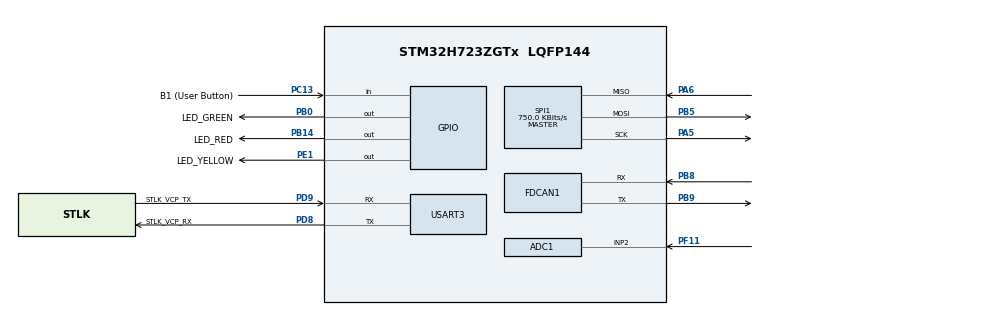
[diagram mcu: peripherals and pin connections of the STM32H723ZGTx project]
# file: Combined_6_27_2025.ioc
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ADC1.Channel-0\#ChannelRegularConversion=ADC_CHANNEL_2
ADC1.ContinuousConvMode=ENABLE
ADC1.ConversionDataManagement=ADC_CONVERSIONDATA_DMA_CIRCULAR
ADC1.EOCSelection=ADC_EOC_SEQ_CONV
ADC1.ExternalTrigConv=ADC_EXTERNALTRIG_T3_TRGO
ADC1.NbrOfConversionFlag=1
ADC1.OffsetNumber-0\#ChannelRegularConversion=ADC_OFFSET_NONE
ADC1.OffsetSignedSaturation-0\#ChannelRegularConversion=DISABLE
ADC1.Rank-0\#ChannelRegularConversion=1
ADC1.Resolution=ADC_RESOLUTION_14B_OPT
ADC1.SamplingTime-0\#ChannelRegularConversion=ADC_SAMPLETIME_64CYCLES_5
ADC1.master=1
CORTEX_M7.default_mode_Activation=1
Dma.ADC1.0.Direction=DMA_PERIPH_TO_MEMORY
Dma.ADC1.0.EventEnable=DISABLE
Dma.ADC1.0.FIFOMode=DMA_FIFOMODE_DISABLE
Dma.ADC1.0.Instance=DMA1_Stream0
Dma.ADC1.0.MemDataAlignment=DMA_MDATAALIGN_HALFWORD
Dma.ADC1.0.MemInc=DMA_MINC_ENABLE
Dma.ADC1.0.Mode=DMA_CIRCULAR
Dma.ADC1.0.PeriphDataAlignment=DMA_PDATAALIGN_HALFWORD
Dma.ADC1.0.PeriphInc=DMA_PINC_DISABLE
Dma.ADC1.0.Polarity=HAL_DMAMUX_REQ_GEN_RISING
Dma.ADC1.0.Priority=DMA_PRIORITY_VERY_HIGH
Dma.ADC1.0.RequestNumber=1
Dma.ADC1.0.SignalID=NONE
Dma.ADC1.0.SyncEnable=DISABLE
Dma.ADC1.0.SyncPolarity=HAL_DMAMUX_SYNC_NO_EVENT
Dma.ADC1.0.SyncRequestNumber=1
Dma.ADC1.0.SyncSignalID=NONE
Dma.Request0=ADC1
FDCAN1.AutoRetransmission=ENABLE
FDCAN1.CalculateBaudRateNominal=500000
FDCAN1.CalculateTimeBitNominal=2000
FDCAN1.CalculateTimeQuantumNominal=20.833333333333332
FDCAN1.DataPrescaler=2
FDCAN1.DataSyncJumpWidth=11
FDCAN1.DataTimeSeg1=12
FDCAN1.DataTimeSeg2=11
FDCAN1.NominalPrescaler=1
FDCAN1.NominalSyncJumpWidth=12
FDCAN1.NominalTimeSeg1=83
FDCAN1.NominalTimeSeg2=12
FDCAN1.RxBufferSize=FDCAN_DATA_BYTES_12
FDCAN1.RxBuffersNbr=1
FDCAN1.RxFifo0ElmtSize=FDCAN_DATA_BYTES_12
FDCAN1.RxFifo1ElmtSize=FDCAN_DATA_BYTES_12
FDCAN1.StdFiltersNbr=1
FDCAN1.TransmitPause=ENABLE
FDCAN1.TxBuffersNbr=1
FDCAN1.TxElmtSize=FDCAN_DATA_BYTES_12
Mcu.Family=STM32H7
Mcu.Name=STM32H723ZGTx
Mcu.Package=LQFP144
NVIC.DMA1_Stream0_IRQn=true\:0\:0\:false\:false\:true\:false\:true\:true
NVIC.PriorityGroup=NVIC_PRIORITYGROUP_4
PA13(JTMS/SWDIO).GPIO_Label=SWDIO
PA13(JTMS/SWDIO).Signal=DEBUG_JTMS-SWDIO
PA14(JTCK/SWCLK).GPIO_Label=SWCLK
PA14(JTCK/SWCLK).Signal=DEBUG_JTCK-SWCLK
PA5.Mode=Full_Duplex_Master
PA5.Signal=SPI1_SCK
PA6.Mode=Full_Duplex_Master
PA6.Signal=SPI1_MISO
PB0.GPIO_Label=LED_GREEN
PB0.Signal=GPIO_Output
PB14.GPIO_Label=LED_RED
PB14.Signal=GPIO_Output
PB5.Mode=Full_Duplex_Master
PB5.Signal=SPI1_MOSI
PB8.Mode=FDCAN_Activate
PB8.Signal=FDCAN1_RX
PB9.Mode=FDCAN_Activate
PB9.Signal=FDCAN1_TX
PC13.GPIO_Label=B1 (User Button)
PC13.Signal=GPIO_Input
PC14-OSC32_IN.Signal=RCC_OSC32_IN
PC15-OSC32_OUT.Signal=RCC_OSC32_OUT
PD8.GPIO_Label=STLK_VCP_RX
PD8.Mode=Asynchronous
PD8.Signal=USART3_TX
PD9.GPIO_Label=STLK_VCP_TX
PD9.Mode=Asynchronous
PD9.Signal=USART3_RX
PE1.GPIO_Label=LED_YELLOW
PE1.Signal=GPIO_Output
PF11.Mode=IN2-Single-Ended
PF11.Signal=ADC1_INP2
ProjectManager.HeapSize=0x200
ProjectManager.StackSize=0x400
ProjectManager.TargetToolchain=STM32CubeIDE
RCC.ADCFreq_Value=48000000
RCC.APB1Freq_Value=96000000
RCC.APB2Freq_Value=96000000
RCC.APB3Freq_Value=96000000
RCC.APB4Freq_Value=96000000
RCC.CortexFreq_Value=192000000
RCC.D1PPRE=RCC_APB3_DIV2
RCC.D2PPRE1=RCC_APB1_DIV2
RCC.D2PPRE2=RCC_APB2_DIV2
RCC.D3PPRE=RCC_APB4_DIV2
RCC.DIVM1=4
RCC.DIVM2=4
RCC.DIVN1=12
RCC.DIVN2=12
RCC.DIVP1=1
RCC.DIVP2=4
RCC.DIVQ1=4
RCC.HCLKFreq_Value=192000000
RCC.HSE_VALUE=8000000
RCC.PLL2FRACN=0
RCC.PLLFRACN=0
RCC.SYSCLKFreq_VALUE=192000000
RCC.SYSCLKSource=RCC_SYSCLKSOURCE_PLLCLK
RCC.USBCLockSelection=RCC_USBCLKSOURCE_HSI48
RCC.USBFreq_Value=48000000
SPI1.BaudRatePrescaler=SPI_BAUDRATEPRESCALER_64
SPI1.CalculateBaudRate=750.0 KBits/s
SPI1.DataSize=SPI_DATASIZE_12BIT
SPI1.Direction=SPI_DIRECTION_2LINES
SPI1.Mode=SPI_MODE_MASTER
SPI1.NSSPMode=SPI_NSS_PULSE_DISABLE
SPI1.VirtualType=VM_MASTER
TIM3.Period=99
TIM3.Prescaler=1919
TIM3.TIM_MasterOutputTrigger=TIM_TRGO_UPDATE
USART3.VirtualMode-Asynchronous=VM_ASYNC
VP_MEMORYMAP_VS_MEMORYMAP.Mode=CurAppReg
VP_TIM3_VS_ClockSourceINT.Mode=Internal
board=NUCLEO-H723ZG

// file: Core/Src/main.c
#include "main.h"

ADC_HandleTypeDef hadc1;
DMA_HandleTypeDef hdma_adc1;
FDCAN_HandleTypeDef hfdcan1;
SPI_HandleTypeDef hspi1;
TIM_HandleTypeDef htim3;
UART_HandleTypeDef huart3;

void SystemClock_Config(void);
 void MPU_Config(void);
 void MX_GPIO_Init(void);
 void MX_DMA_Init(void);
 void MX_ADC1_Init(void);
 void MX_TIM3_Init(void);
 void MX_FDCAN1_Init(void);
 void MX_SPI1_Init(void);
 void MX_USART3_UART_Init(void);

int testmain(void)
{

  /* MPU Configuration--------------------------------------------------------*/
  MPU_Config();

  /* MCU Configuration--------------------------------------------------------*/

  /* Reset of all peripherals, Initializes the Flash interface and the Systick. */
  HAL_Init();

  /* Configure the system clock */
  SystemClock_Config();

  /* Initialize all configured peripherals */
  MX_GPIO_Init();
  MX_DMA_Init();
  MX_ADC1_Init();
  MX_TIM3_Init();
  MX_FDCAN1_Init();
  MX_SPI1_Init();
  MX_USART3_UART_Init();
  /* USER CODE BEGIN 2 */
uint8_t buffer_uart[] = "Hello World";
  /* USER CODE END 2 */

  /* Infinite loop */
  while (1)
  {

  }
}

void SystemClock_Config(void)
{
  RCC_OscInitTypeDef RCC_OscInitStruct = {0};
  RCC_ClkInitTypeDef RCC_ClkInitStruct = {0};

  /** Supply configuration update enable
  */
  HAL_PWREx_ConfigSupply(PWR_LDO_SUPPLY);

  /** Configure the main internal regulator output voltage
  */
  __HAL_PWR_VOLTAGESCALING_CONFIG(PWR_REGULATOR_VOLTAGE_SCALE1);

  while(!__HAL_PWR_GET_FLAG(PWR_FLAG_VOSRDY)) {}

  /** Initializes the RCC Oscillators according to the specified parameters
  * in the RCC_OscInitTypeDef structure.
  */
  RCC_OscInitStruct.OscillatorType = RCC_OSCILLATORTYPE_HSI;
  RCC_OscInitStruct.HSIState = RCC_HSI_DIV1;
  RCC_OscInitStruct.HSICalibrationValue = 64;
  RCC_OscInitStruct.PLL.PLLState = RCC_PLL_ON;
  RCC_OscInitStruct.PLL.PLLSource = RCC_PLLSOURCE_HSI;
  RCC_OscInitStruct.PLL.PLLM = 4;
  RCC_OscInitStruct.PLL.PLLN = 12;
  RCC_OscInitStruct.PLL.PLLP = 1;
  RCC_OscInitStruct.PLL.PLLQ = 4;
  RCC_OscInitStruct.PLL.PLLR = 2;
  RCC_OscInitStruct.PLL.PLLRGE = RCC_PLL1VCIRANGE_3;
  RCC_OscInitStruct.PLL.PLLVCOSEL = RCC_PLL1VCOWIDE;
  RCC_OscInitStruct.PLL.PLLFRACN = 0;
  if (HAL_RCC_OscConfig(&RCC_OscInitStruct) != HAL_OK)
  {
    Error_Handler();
  }

  /** Initializes the CPU, AHB and APB buses clocks
  */
  RCC_ClkInitStruct.ClockType = RCC_CLOCKTYPE_HCLK|RCC_CLOCKTYPE_SYSCLK
                              |RCC_CLOCKTYPE_PCLK1|RCC_CLOCKTYPE_PCLK2
                              |RCC_CLOCKTYPE_D3PCLK1|RCC_CLOCKTYPE_D1PCLK1;
  RCC_ClkInitStruct.SYSCLKSource = RCC_SYSCLKSOURCE_PLLCLK;
  RCC_ClkInitStruct.SYSCLKDivider = RCC_SYSCLK_DIV1;
  RCC_ClkInitStruct.AHBCLKDivider = RCC_HCLK_DIV1;
  RCC_ClkInitStruct.APB3CLKDivider = RCC_APB3_DIV2;
  RCC_ClkInitStruct.APB1CLKDivider = RCC_APB1_DIV2;
  RCC_ClkInitStruct.APB2CLKDivider = RCC_APB2_DIV2;
  RCC_ClkInitStruct.APB4CLKDivider = RCC_APB4_DIV2;

  if (HAL_RCC_ClockConfig(&RCC_ClkInitStruct, FLASH_LATENCY_2) != HAL_OK)
  {
    Error_Handler();
  }
}

void MX_ADC1_Init(void)
{

  ADC_MultiModeTypeDef multimode = {0};
  ADC_ChannelConfTypeDef sConfig = {0};

  /** Common config
  */
  hadc1.Instance = ADC1;
  hadc1.Init.ClockPrescaler = ADC_CLOCK_ASYNC_DIV1;
  hadc1.Init.Resolution = ADC_RESOLUTION_14B;
  hadc1.Init.ScanConvMode = ADC_SCAN_DISABLE;
  hadc1.Init.EOCSelection = ADC_EOC_SEQ_CONV;
  hadc1.Init.LowPowerAutoWait = DISABLE;
  hadc1.Init.ContinuousConvMode = ENABLE;
  hadc1.Init.NbrOfConversion = 1;
  hadc1.Init.DiscontinuousConvMode = DISABLE;
  hadc1.Init.ExternalTrigConv = ADC_EXTERNALTRIG_T3_TRGO;
  hadc1.Init.ExternalTrigConvEdge = ADC_EXTERNALTRIGCONVEDGE_RISING;
  hadc1.Init.ConversionDataManagement = ADC_CONVERSIONDATA_DMA_CIRCULAR;
  hadc1.Init.Overrun = ADC_OVR_DATA_PRESERVED;
  hadc1.Init.LeftBitShift = ADC_LEFTBITSHIFT_NONE;
  hadc1.Init.OversamplingMode = DISABLE;
  hadc1.Init.Oversampling.Ratio = 1;
  if (HAL_ADC_Init(&hadc1) != HAL_OK)
  {
    Error_Handler();
  }

  /** Configure the ADC multi-mode
  */
  multimode.Mode = ADC_MODE_INDEPENDENT;
  if (HAL_ADCEx_MultiModeConfigChannel(&hadc1, &multimode) != HAL_OK)
  {
    Error_Handler();
  }

  /** Configure Regular Channel
  */
  sConfig.Channel = ADC_CHANNEL_2;
  sConfig.Rank = ADC_REGULAR_RANK_1;
  sConfig.SamplingTime = ADC_SAMPLETIME_64CYCLES_5;
  sConfig.SingleDiff = ADC_SINGLE_ENDED;
  sConfig.OffsetNumber = ADC_OFFSET_NONE;
  sConfig.Offset = 0;
  sConfig.OffsetSignedSaturation = DISABLE;
  if (HAL_ADC_ConfigChannel(&hadc1, &sConfig) != HAL_OK)
  {
    Error_Handler();
  }

}

void MX_FDCAN1_Init(void)
{

  hfdcan1.Instance = FDCAN1;
  hfdcan1.Init.FrameFormat = FDCAN_FRAME_CLASSIC;
  hfdcan1.Init.Mode = FDCAN_MODE_NORMAL;
  hfdcan1.Init.AutoRetransmission = ENABLE;
  hfdcan1.Init.TransmitPause = DISABLE;
  hfdcan1.Init.ProtocolException = DISABLE;
  hfdcan1.Init.NominalPrescaler = 1;
  hfdcan1.Init.NominalSyncJumpWidth = 12;
  hfdcan1.Init.NominalTimeSeg1 = 83;
  hfdcan1.Init.NominalTimeSeg2 = 12;
  hfdcan1.Init.DataPrescaler = 2;
  hfdcan1.Init.DataSyncJumpWidth = 11;
  hfdcan1.Init.DataTimeSeg1 = 12;
  hfdcan1.Init.DataTimeSeg2 = 11;
  hfdcan1.Init.MessageRAMOffset = 0;
  hfdcan1.Init.StdFiltersNbr = 1;
  hfdcan1.Init.ExtFiltersNbr = 0;
  hfdcan1.Init.RxFifo0ElmtsNbr = 0;
  hfdcan1.Init.RxFifo0ElmtSize = FDCAN_DATA_BYTES_12;
  hfdcan1.Init.RxFifo1ElmtsNbr = 0;
  hfdcan1.Init.RxFifo1ElmtSize = FDCAN_DATA_BYTES_12;
  hfdcan1.Init.RxBuffersNbr = 1;
  hfdcan1.Init.RxBufferSize = FDCAN_DATA_BYTES_12;
  hfdcan1.Init.TxEventsNbr = 0;
  hfdcan1.Init.TxBuffersNbr = 1;
  hfdcan1.Init.TxFifoQueueElmtsNbr = 0;
  hfdcan1.Init.TxFifoQueueMode = FDCAN_TX_FIFO_OPERATION;
  hfdcan1.Init.TxElmtSize = FDCAN_DATA_BYTES_12;
  if (HAL_FDCAN_Init(&hfdcan1) != HAL_OK)
  {
    Error_Handler();
  }

}

void MX_SPI1_Init(void)
{

  /* SPI1 parameter configuration*/
  hspi1.Instance = SPI1;
  hspi1.Init.Mode = SPI_MODE_MASTER;
  hspi1.Init.Direction = SPI_DIRECTION_2LINES;
  hspi1.Init.DataSize = SPI_DATASIZE_12BIT;
  hspi1.Init.CLKPolarity = SPI_POLARITY_LOW;
  hspi1.Init.CLKPhase = SPI_PHASE_1EDGE;
  hspi1.Init.NSS = SPI_NSS_SOFT;
  hspi1.Init.BaudRatePrescaler = SPI_BAUDRATEPRESCALER_64;
  hspi1.Init.FirstBit = SPI_FIRSTBIT_MSB;
  hspi1.Init.TIMode = SPI_TIMODE_DISABLE;
  hspi1.Init.CRCCalculation = SPI_CRCCALCULATION_DISABLE;
  hspi1.Init.CRCPolynomial = 0x0;
  hspi1.Init.NSSPMode = SPI_NSS_PULSE_DISABLE;
  hspi1.Init.NSSPolarity = SPI_NSS_POLARITY_LOW;
  hspi1.Init.FifoThreshold = SPI_FIFO_THRESHOLD_01DATA;
  hspi1.Init.TxCRCInitializationPattern = SPI_CRC_INITIALIZATION_ALL_ZERO_PATTERN;
  hspi1.Init.RxCRCInitializationPattern = SPI_CRC_INITIALIZATION_ALL_ZERO_PATTERN;
  hspi1.Init.MasterSSIdleness = SPI_MASTER_SS_IDLENESS_00CYCLE;
  hspi1.Init.MasterInterDataIdleness = SPI_MASTER_INTERDATA_IDLENESS_00CYCLE;
  hspi1.Init.MasterReceiverAutoSusp = SPI_MASTER_RX_AUTOSUSP_DISABLE;
  hspi1.Init.MasterKeepIOState = SPI_MASTER_KEEP_IO_STATE_DISABLE;
  hspi1.Init.IOSwap = SPI_IO_SWAP_DISABLE;
  if (HAL_SPI_Init(&hspi1) != HAL_OK)
  {
    Error_Handler();
  }

}

void MX_TIM3_Init(void)
{

  TIM_ClockConfigTypeDef sClockSourceConfig = {0};
  TIM_MasterConfigTypeDef sMasterConfig = {0};

  htim3.Instance = TIM3;
  htim3.Init.Prescaler = 1919;
  htim3.Init.CounterMode = TIM_COUNTERMODE_UP;
  htim3.Init.Period = 99;
  htim3.Init.ClockDivision = TIM_CLOCKDIVISION_DIV1;
  htim3.Init.AutoReloadPreload = TIM_AUTORELOAD_PRELOAD_DISABLE;
  if (HAL_TIM_Base_Init(&htim3) != HAL_OK)
  {
    Error_Handler();
  }
  sClockSourceConfig.ClockSource = TIM_CLOCKSOURCE_INTERNAL;
  if (HAL_TIM_ConfigClockSource(&htim3, &sClockSourceConfig) != HAL_OK)
  {
    Error_Handler();
  }
  sMasterConfig.MasterOutputTrigger = TIM_TRGO_UPDATE;
  sMasterConfig.MasterSlaveMode = TIM_MASTERSLAVEMODE_DISABLE;
  if (HAL_TIMEx_MasterConfigSynchronization(&htim3, &sMasterConfig) != HAL_OK)
  {
    Error_Handler();
  }

}

void MX_USART3_UART_Init(void)
{

  huart3.Instance = USART3;
  huart3.Init.BaudRate = 115200;
  huart3.Init.WordLength = UART_WORDLENGTH_8B;
  huart3.Init.StopBits = UART_STOPBITS_1;
  huart3.Init.Parity = UART_PARITY_NONE;
  huart3.Init.Mode = UART_MODE_TX_RX;
  huart3.Init.HwFlowCtl = UART_HWCONTROL_NONE;
  huart3.Init.OverSampling = UART_OVERSAMPLING_16;
  huart3.Init.OneBitSampling = UART_ONE_BIT_SAMPLE_DISABLE;
  huart3.Init.ClockPrescaler = UART_PRESCALER_DIV1;
  huart3.AdvancedInit.AdvFeatureInit = UART_ADVFEATURE_NO_INIT;
  if (HAL_UART_Init(&huart3) != HAL_OK)
  {
    Error_Handler();
  }
  if (HAL_UARTEx_SetTxFifoThreshold(&huart3, UART_TXFIFO_THRESHOLD_1_8) != HAL_OK)
  {
    Error_Handler();
  }
  if (HAL_UARTEx_SetRxFifoThreshold(&huart3, UART_RXFIFO_THRESHOLD_1_8) != HAL_OK)
  {
    Error_Handler();
  }
  if (HAL_UARTEx_DisableFifoMode(&huart3) != HAL_OK)
  {
    Error_Handler();
  }

}

void MX_DMA_Init(void)
{

  /* DMA controller clock enable */
  __HAL_RCC_DMA1_CLK_ENABLE();

  /* DMA interrupt init */
  /* DMA1_Stream0_IRQn interrupt configuration */
  HAL_NVIC_SetPriority(DMA1_Stream0_IRQn, 0, 0);
  HAL_NVIC_EnableIRQ(DMA1_Stream0_IRQn);

}

void MX_GPIO_Init(void)
{
  GPIO_InitTypeDef GPIO_InitStruct = {0};

  /* GPIO Ports Clock Enable */
  __HAL_RCC_GPIOC_CLK_ENABLE();
  __HAL_RCC_GPIOA_CLK_ENABLE();
  __HAL_RCC_GPIOB_CLK_ENABLE();
  __HAL_RCC_GPIOF_CLK_ENABLE();
  __HAL_RCC_GPIOD_CLK_ENABLE();
  __HAL_RCC_GPIOE_CLK_ENABLE();

  /*Configure GPIO pin Output Level */
  HAL_GPIO_WritePin(GPIOB, LED_GREEN_Pin|LED_RED_Pin, GPIO_PIN_RESET);

  /*Configure GPIO pin Output Level */
  HAL_GPIO_WritePin(LED_YELLOW_GPIO_Port, LED_YELLOW_Pin, GPIO_PIN_RESET);

  /*Configure GPIO pin : B1_Pin */
  GPIO_InitStruct.Pin = B1_Pin;
  GPIO_InitStruct.Mode = GPIO_MODE_INPUT;
  GPIO_InitStruct.Pull = GPIO_NOPULL;
  HAL_GPIO_Init(B1_GPIO_Port, &GPIO_InitStruct);

  /*Configure GPIO pins : LED_GREEN_Pin LED_RED_Pin */
  GPIO_InitStruct.Pin = LED_GREEN_Pin|LED_RED_Pin;
  GPIO_InitStruct.Mode = GPIO_MODE_OUTPUT_PP;
  GPIO_InitStruct.Pull = GPIO_NOPULL;
  GPIO_InitStruct.Speed = GPIO_SPEED_FREQ_LOW;
  HAL_GPIO_Init(GPIOB, &GPIO_InitStruct);

  /*Configure GPIO pin : LED_YELLOW_Pin */
  GPIO_InitStruct.Pin = LED_YELLOW_Pin;
  GPIO_InitStruct.Mode = GPIO_MODE_OUTPUT_PP;
  GPIO_InitStruct.Pull = GPIO_NOPULL;
  GPIO_InitStruct.Speed = GPIO_SPEED_FREQ_LOW;
  HAL_GPIO_Init(LED_YELLOW_GPIO_Port, &GPIO_InitStruct);

}

 /* MPU Configuration */

void MPU_Config(void)
{
  MPU_Region_InitTypeDef MPU_InitStruct = {0};

  /* Disables the MPU */
  HAL_MPU_Disable();

  /** Initializes and configures the Region and the memory to be protected
  */
  MPU_InitStruct.Enable = MPU_REGION_ENABLE;
  MPU_InitStruct.Number = MPU_REGION_NUMBER0;
  MPU_InitStruct.BaseAddress = 0x0;
  MPU_InitStruct.Size = MPU_REGION_SIZE_4GB;
  MPU_InitStruct.SubRegionDisable = 0x87;
  MPU_InitStruct.TypeExtField = MPU_TEX_LEVEL0;
  MPU_InitStruct.AccessPermission = MPU_REGION_NO_ACCESS;
  MPU_InitStruct.DisableExec = MPU_INSTRUCTION_ACCESS_DISABLE;
  MPU_InitStruct.IsShareable = MPU_ACCESS_SHAREABLE;
  MPU_InitStruct.IsCacheable = MPU_ACCESS_NOT_CACHEABLE;
  MPU_InitStruct.IsBufferable = MPU_ACCESS_NOT_BUFFERABLE;

  HAL_MPU_ConfigRegion(&MPU_InitStruct);
  /* Enables the MPU */
  HAL_MPU_Enable(MPU_PRIVILEGED_DEFAULT);

}

void Error_Handler(void)
{
  __disable_irq();
  while (1)
  {
  }
}
